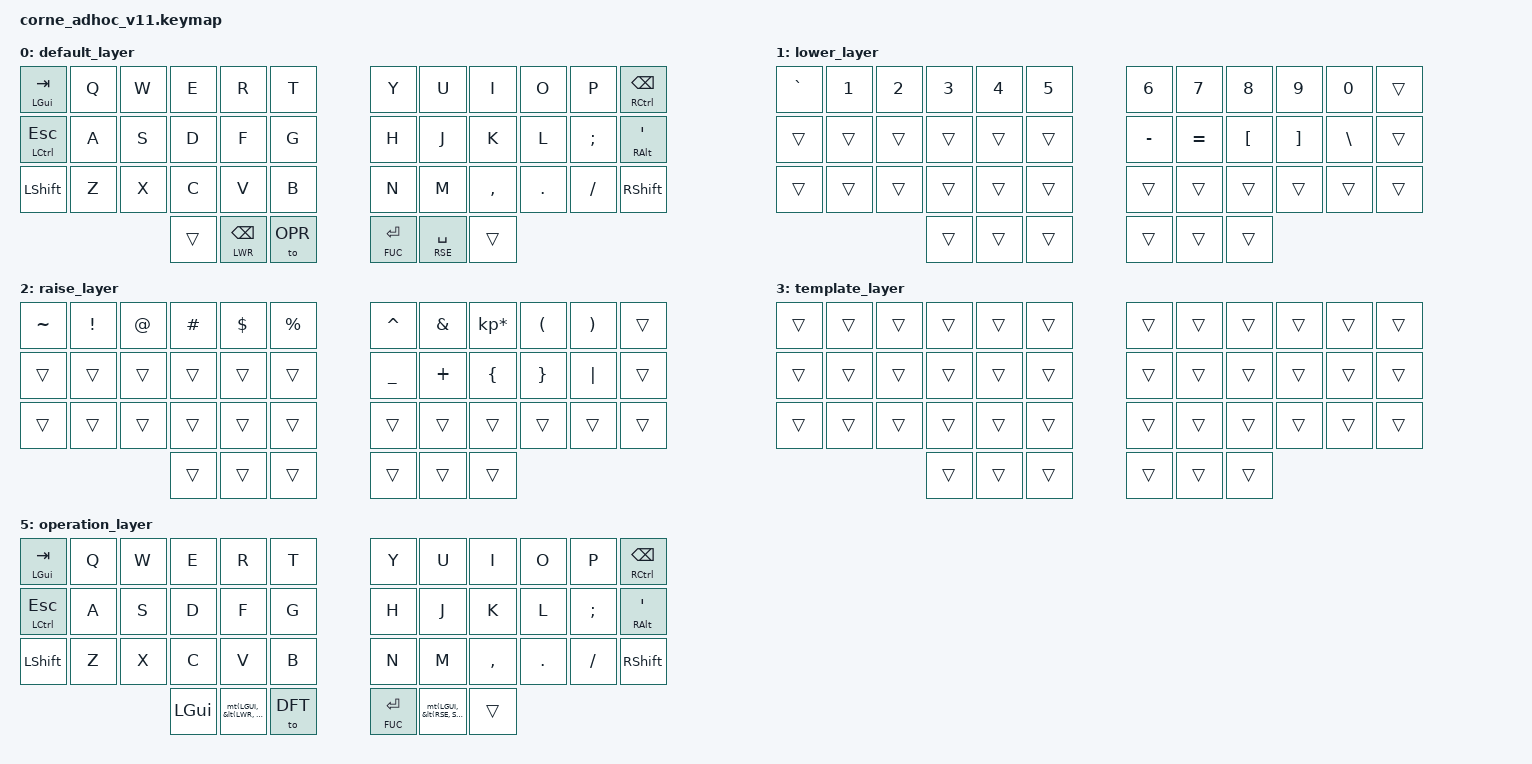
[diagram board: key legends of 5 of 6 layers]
/*
 * Copyright (c) 2020 The ZMK Contributors
 *
 * SPDX-License-Identifier: MIT
 *
 * Reference: https://zmk.dev/docs/keymaps/behaviors/key-press
 *
 */

#include <behaviors.dtsi>
#include <dt-bindings/zmk/keys.h>
#include <dt-bindings/zmk/bt.h>
#include <dt-bindings/zmk/rgb.h>

&led_strip {
    chain-length = <27>;
};

// Define the custom macro
// reference: https://zmk.dev/docs/keymaps/behaviors/macros
/ {
    macros {
        // switch input method
        macos_input: macos_input {
            compatible = "zmk,behavior-macro";
            #binding-cells = <0>;
            bindings
                = <&macro_press &kp LCTRL>
                , <&macro_press &kp LALT>
                , <&macro_tap &kp SPACE>
                , <&macro_release &kp LALT>
                , <&macro_release &kp LCTRL>
                ;
        };
        // alt_backspace ALT_BS
        alt_backspace: alt_backspace {
            compatible = "zmk,behavior-macro";
            #binding-cells = <0>;
            bindings
                = <&macro_press &kp LALT>
                , <&macro_tap &kp BSPC>
                , <&macro_release &kp LALT>
                ;
        };
        // MAC_SC
        macos_screenshot: macos_screenshot {
            compatible = "zmk,behavior-macro";
            #binding-cells = <0>;
            bindings
                = <&macro_press &kp LGUI>
                , <&macro_press &kp LCTRL>
                , <&macro_press &kp LSHFT>
                , <&macro_tap &kp N4>
                , <&macro_release &kp LSHFT>
                , <&macro_release &kp LCTRL>
                , <&macro_release &kp LGUI>
                ;
        };
        // MAC_SA
        macos_screenshot_with_annotation: macos_screenshot_with_annotation {
            compatible = "zmk,behavior-macro";
            #binding-cells = <0>;
            bindings
                = <&macro_press &kp LGUI>
                , <&macro_press &kp LSHFT>
                , <&macro_tap &kp N4>
                , <&macro_release &kp LSHFT>
                , <&macro_release &kp LGUI>
                ;
        };
        ctrl_alt_left: ctrl_alt_left {
            compatible = "zmk,behavior-macro";
            #binding-cells = <0>;
            bindings
                = <&macro_press &kp LCTRL>
                , <&macro_press &kp LALT>
                , <&macro_tap &kp LEFT>
                , <&macro_release &kp LALT>
                , <&macro_release &kp LCTRL>
                ;
        };
        ctrl_alt_right: ctrl_alt_right {
            compatible = "zmk,behavior-macro";
            #binding-cells = <0>;
            bindings
                = <&macro_press &kp LCTRL>
                , <&macro_press &kp LALT>
                , <&macro_tap &kp RIGHT>
                , <&macro_release &kp LALT>
                , <&macro_release &kp LCTRL>
                ;
        };
        ctrl_alt_up: ctrl_alt_up {
            compatible = "zmk,behavior-macro";
            #binding-cells = <0>;
            bindings
                = <&macro_press &kp LCTRL>
                , <&macro_press &kp LALT>
                , <&macro_tap &kp UP>
                , <&macro_release &kp LALT>
                , <&macro_release &kp LCTRL>
                ;
        };
        ctrl_alt_down: ctrl_alt_down {
            compatible = "zmk,behavior-macro";
            #binding-cells = <0>;
            bindings
                = <&macro_press &kp LCTRL>
                , <&macro_press &kp LALT>
                , <&macro_tap &kp DOWN>
                , <&macro_release &kp LALT>
                , <&macro_release &kp LCTRL>
                ;
        };
        ctrl_alt_enter: ctrl_alt_enter {
            compatible = "zmk,behavior-macro";
            #binding-cells = <0>;
            bindings
                = <&macro_press &kp LCTRL>
                , <&macro_press &kp LALT>
                , <&macro_tap &kp RET>
                , <&macro_release &kp LALT>
                , <&macro_release &kp LCTRL>
                ;
        };
        // cmd_grave
        cmd_grave: cmd_grave {
            compatible = "zmk,behavior-macro";
            #binding-cells = <0>;
            bindings
                = <&macro_press &kp LGUI>
                , <&macro_tap &kp GRAVE>
                , <&macro_release &kp LGUI>
                ;
        };
        // cmd_1
        cmd_1: cmd_1 {
            compatible = "zmk,behavior-macro";
            #binding-cells = <0>;
            bindings
                = <&macro_press &kp LGUI>
                , <&macro_tap &kp N1>
                , <&macro_release &kp LGUI>
                ;
        };
        // cmd_2
        cmd_2: cmd_2 {
            compatible = "zmk,behavior-macro";
            #binding-cells = <0>;
            bindings
                = <&macro_press &kp LGUI>
                , <&macro_tap &kp N2>
                , <&macro_release &kp LGUI>
                ;
        };
        // cmd_3
        cmd_3: cmd_3 {
            compatible = "zmk,behavior-macro";
            #binding-cells = <0>;
            bindings
                = <&macro_press &kp LGUI>
                , <&macro_tap &kp N3>
                , <&macro_release &kp LGUI>
                ;
        };
        // cmd_4
        cmd_4: cmd_4 {
            compatible = "zmk,behavior-macro";
            #binding-cells = <0>;
            bindings
                = <&macro_press &kp LGUI>
                , <&macro_tap &kp N4>
                , <&macro_release &kp LGUI>
                ;
        };
        // cmd_5
        cmd_5: cmd_5 {
            compatible = "zmk,behavior-macro";
            #binding-cells = <0>;
            bindings
                = <&macro_press &kp LGUI>
                , <&macro_tap &kp N5>
                , <&macro_release &kp LGUI>
                ;
        };
    };
};

#define DEFAULT 0
#define DFT 0
#define LWR 1
#define RSE 2
#define TMP 3
#define FUC 4
#define OPR 5

#define mac_sc macos_screenshot
#define mac_sca macos_screenshot_with_annotation
#define mac_in macos_input

/ {
        keymap {
                compatible = "zmk,keymap";

                default_layer {
// Neovim Layer - Basic
// DFT
// -----------------------------------------------------------------------------------------
// | TAB / LGUI  |  Q  |  W  |  E   |  R         |  T  | | Y   |  U        |  I  |  O  |  P  | BSPC / RCTRL |
// | ESC / LCTRL |  A  |  S  |  D   |  F         |  G  | | H   |  J        |  K  |  L  |  ;  | ' / RALT     |
// | LSHFT       |  Z  |  X  |  C   |  V         |  B  | | N   |  M        |  ,  |  .  |  /  | RSHFT        |
//                           |      | BSPC / LWR | OPR | | ENT / FUC | SPC / RSE |     |
                        bindings = <
   &mt LGUI TAB  &kp Q &kp W &kp E  &kp R        &kp T   &kp Y         &kp U         &kp I     &kp O   &kp P    &mt RCTRL BSPC
   &mt LCTRL ESC &kp A &kp S &kp D  &kp F        &kp G   &kp H         &kp J         &kp K     &kp L   &kp SEMI &mt RALT SQT
   &kp LSHFT     &kp Z &kp X &kp C  &kp V        &kp B   &kp N         &kp M         &kp COMMA &kp DOT &kp FSLH &kp RSHFT
                             &trans &lt LWR BSPC &to OPR &lt FUC RET   &lt RSE SPACE &trans
                        >;
                };
                lower_layer {
// Neovim Layer - First Hop
// LWR
// -----------------------------------------------------------------------------------------
// | `      | 1   | 2      |  3    |  4     | 5     | |  6  |  7  | 8   |  9  |  0  | |
// |        |     |        |       |        |       | |  -  |  =  |  [  |  ]  |  \  | |
// |        |     |        |       |        |       | |     |     |     |     |     | |
//                         |       |        |       | |     |     |     |
                        bindings = <
   &kp GRAVE &kp N1  &kp N2 &kp N3   &kp N4   &kp N5 &kp N6    &kp N7    &kp N8   &kp N9   &kp N0   &trans
   &trans    &trans  &trans &trans   &trans   &trans &kp MINUS &kp EQUAL &kp LBKT &kp RBKT &kp BSLH &trans
   &trans    &trans  &trans &trans   &trans   &trans &trans    &trans    &trans   &trans   &trans   &trans
                            &trans   &trans   &trans &trans    &trans    &trans
                        >;
                };
                raise_layer {
// Neovim Layer - Second Hop
// RSE
// -----------------------------------------------------------------------------------------
// | ~        |   !   |   @      |   #     |   $   |   %   |   |  ^  |  &  |  *  |  (  |  )  | |
// |          |       |          |         |       |       |   |  _  |  +  |  {  |  }  | "|" | |
// |          |       |          |         |       |       |   |     |     |     |     |     | |
//                               |         |       |       |   |     |     |     |
                        bindings = <
   &kp TILDE &kp EXCL &kp AT &kp HASH &kp DLLR &kp PRCNT &kp CARET &kp AMPS &kp KP_MULTIPLY &kp LPAR &kp RPAR &trans
   &trans    &trans   &trans &trans   &trans   &trans    &kp UNDER &kp PLUS &kp LBRC        &kp RBRC &kp PIPE &trans
   &trans    &trans   &trans &trans   &trans   &trans    &trans    &trans   &trans          &trans   &trans   &trans
                             &trans   &trans   &trans    &trans    &trans   &trans
                        >;
                };
                template_layer {
// Template Layer: Do Not Change!
// TMP
// Seperation Layer Between Neovim Layer, and other layers, including:
// Function Layer and Operation Layer
// -----------------------------------------------------------------------------------------
// | | | | | | | | | | | | | |
// | | | | | | | | | | | | | |
// | | | | | | | | | | | | | |
//       | | | | | | | |
                        bindings = <
   &trans &trans &trans &trans &trans &trans &trans &trans &trans &trans &trans &trans
   &trans &trans &trans &trans &trans &trans &trans &trans &trans &trans &trans &trans
   &trans &trans &trans &trans &trans &trans &trans &trans &trans &trans &trans &trans
                 &trans &trans &trans &trans &trans &trans
                        >;
                };
                function_layer {
// Function Layer
// FUC
// Provide Bluetooth and RGB control.
// -----------------------------------------------------------------------------------------
// | | BT0     | BT1     | BT2     | BT3     | BT Clear | | | | | | | |
// | | RGB_TOG | RGB_EFF | RGB_HUI | RGB_HUD |          | | | | | | | |
// | | | | | | | | | | | | | |
//       | | | | | | | |
                        bindings = <
   &trans &bt BT_SEL 0   &bt BT_SEL 1    &bt BT_SEL 2    &bt BT_SEL 3    &bt BT_CLR  &trans &trans &trans &trans &trans
   &trans &rgb_ug GB_TOG &rgb_ug RGB_EFF &rgb_ug RGB_HUI &rgb_ug RGB_HUD &trans      &trans &trans &trans &trans &trans
   &trans &mac_sc        &mac_sca        &trans          &mac_in         &trans      &trans &trans &trans &trans &trans &trans
                         &trans          &trans          &trans          &trans      &trans &trans
                        >;
                };
                operation_layer {
// Operation Layer 1
// OPR
// A copy of default layer, but with LGUI added in thumb keys.
// -----------------------------------------------------------------------------------------
// | | | | | | | | | | | | | |
// | | | | | | | | | | | | | |
// | | | | | | | | | | | | | |
//       | | | | | | | |
                        bindings = <
   &mt LGUI TAB  &kp Q &kp W     &kp E  &kp R   &kp T   &kp Y         &kp U       &kp I     &kp O   &kp P    &mt RCTRL BSPC
   &mt LCTRL ESC &kp A &kp S     &kp D  &kp F   &kp G   &kp H         &kp J       &kp K     &kp L   &kp SEMI &mt RALT SQT
   &kp LSHFT     &kp Z &kp X     &kp C  &kp V   &kp B   &kp N         &kp M       &kp COMMA &kp DOT &kp FSLH &kp RSHFT
                        &kp LGUI &mt(LGUI, &lt(LWR, BSPC)) &to DFT    &lt FUC RET &mt(LGUI, &lt(RSE, SPACE)) &trans
                        >;
                };
        };
};
